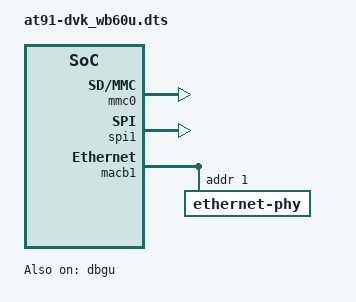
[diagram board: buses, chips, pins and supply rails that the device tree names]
// SPDX-License-Identifier: GPL-2.0
/*
 * at91-dvk_wb60u.dts - Device Tree file for the WB60 board
 *
 *  Copyright (C) 2020 Laird Connectivity,
 *		  2020 Boris Krasnovskiy <boris.krasnovskiy@lairdconnect.com>
 *
 * Licensed under GPLv2 or later.
 */

/dts-v1/;

#include "at91-som60.dtsi"
#include "at91-wb60u.dtsi"

&pinctrl {
	board {
		pinctrl_mmc0_cd: mmc0_cd {
			atmel,pins =
				<AT91_PIOC 26 AT91_PERIPH_GPIO AT91_PINCTRL_PULL_UP_DEGLITCH>;
		};

		pinctrl_spi1_cs: spi1_cs {
			atmel,pins =
				<AT91_PIOC 25 AT91_PERIPH_A AT91_PINCTRL_NONE>;
		};
	};
};

&mmc0 {
	pinctrl-names = "default";
	pinctrl-0 = <&pinctrl_mmc0_clk_cmd_dat0 &pinctrl_mmc0_dat1_3 &pinctrl_mmc0_cd>;

	status = "okay";

	slot@0 {
		reg = <0>;
		bus-width = <4>;
		cd-gpios = <&pioC 26 GPIO_ACTIVE_LOW>;
	};
};

&spi1 {
	pinctrl-names = "default";
	pinctrl-0 = <&pinctrl_spi1 &pinctrl_spi1_cs>;

	status = "okay";
};

&macb1 {
	status = "okay";

	ethernet-phy@1 {
		reg = <1>;
	};
};

&dbgu {
	atmel,use-dma-rx;

	status = "okay";
};
